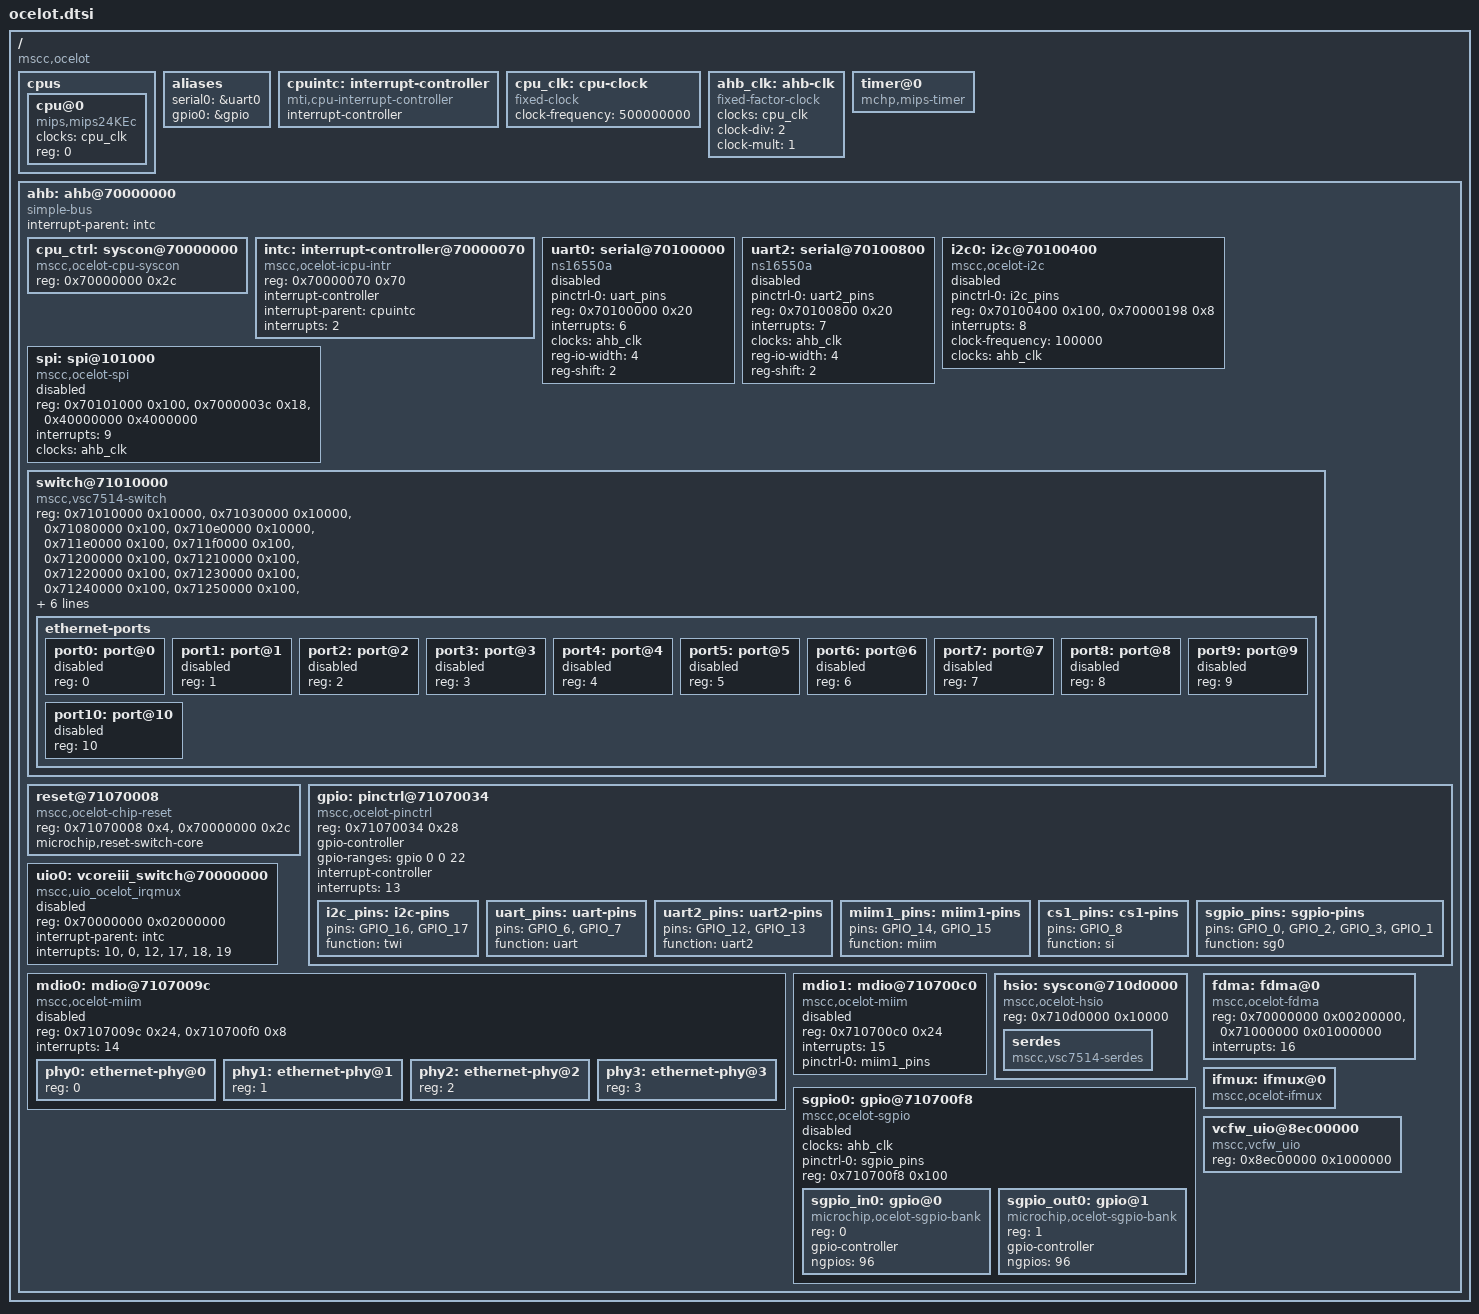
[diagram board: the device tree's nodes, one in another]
// SPDX-License-Identifier: (GPL-2.0 OR MIT)
/* Copyright (c) 2017 Microsemi Corporation */

#include <dt-bindings/gpio/gpio.h>

/ {
	#address-cells = <1>;
	#size-cells = <1>;
	compatible = "mscc,ocelot";

	cpus {
		#address-cells = <1>;
		#size-cells = <0>;

		cpu@0 {
			compatible = "mips,mips24KEc";
			device_type = "cpu";
			clocks = <&cpu_clk>;
			reg = <0>;
		};
	};

	aliases {
		serial0 = &uart0;
		gpio0 = &gpio;
	};

	cpuintc: interrupt-controller {
		#address-cells = <0>;
		#interrupt-cells = <1>;
		interrupt-controller;
		compatible = "mti,cpu-interrupt-controller";
	};

	cpu_clk: cpu-clock {
		compatible = "fixed-clock";
		#clock-cells = <0>;
		clock-frequency = <500000000>;
	};

	ahb_clk: ahb-clk {
		compatible = "fixed-factor-clock";
		#clock-cells = <0>;
		clocks = <&cpu_clk>;
		clock-div = <2>;
		clock-mult = <1>;
	};

	/* Satisfy the platforms need of at least one timer */
	timer@0 {
		compatible = "mchp,mips-timer";
	};

	ahb: ahb@70000000 {
		compatible = "simple-bus";
		#address-cells = <1>;
		#size-cells = <1>;
		ranges;

		interrupt-parent = <&intc>;

		cpu_ctrl: syscon@70000000 {
			compatible = "mscc,ocelot-cpu-syscon", "syscon";
			reg = <0x70000000 0x2c>;
		};

		intc: interrupt-controller@70000070 {
			compatible = "mscc,ocelot-icpu-intr";
			reg = <0x70000070 0x70>;
			#interrupt-cells = <1>;
			interrupt-controller;
			interrupt-parent = <&cpuintc>;
			interrupts = <2>;
		};

		uart0: serial@70100000 {
			pinctrl-0 = <&uart_pins>;
			pinctrl-names = "default";
			compatible = "ns16550a";
			reg = <0x70100000 0x20>;
			interrupts = <6>;
			clocks = <&ahb_clk>;
			reg-io-width = <4>;
			reg-shift = <2>;

			status = "disabled";
		};

		uart2: serial@70100800 {
			pinctrl-0 = <&uart2_pins>;
			pinctrl-names = "default";
			compatible = "ns16550a";
			reg = <0x70100800 0x20>;
			interrupts = <7>;
			clocks = <&ahb_clk>;
			reg-io-width = <4>;
			reg-shift = <2>;

			status = "disabled";
		};

		i2c0: i2c@70100400 {
			compatible = "mscc,ocelot-i2c", "snps,designware-i2c";
			status = "disabled";
			pinctrl-0 = <&i2c_pins>;
			pinctrl-names = "default";
			reg = <0x70100400 0x100>, <0x70000198 0x8>;
			#address-cells = <1>;
			#size-cells = <0>;
			interrupts = <8>;
			clock-frequency = <100000>;
			clocks = <&ahb_clk>;
		};

		spi: spi@101000 {
			compatible = "mscc,ocelot-spi";
			#address-cells = <1>;
			#size-cells = <0>;
			reg = <0x70101000 0x100>, <0x7000003c 0x18>, <0x40000000 0x4000000>;
			interrupts = <9>;
			clocks = <&ahb_clk>;

			status = "disabled";
		};

		switch@71010000 {
			compatible = "mscc,vsc7514-switch";
			reg = <0x71010000 0x10000>,
			      <0x71030000 0x10000>,
			      <0x71080000 0x100>,
			      <0x710e0000 0x10000>,
			      <0x711e0000 0x100>,
			      <0x711f0000 0x100>,
			      <0x71200000 0x100>,
			      <0x71210000 0x100>,
			      <0x71220000 0x100>,
			      <0x71230000 0x100>,
			      <0x71240000 0x100>,
			      <0x71250000 0x100>,
			      <0x71260000 0x100>,
			      <0x71270000 0x100>,
			      <0x71280000 0x100>,
			      <0x71800000 0x80000>,
			      <0x71880000 0x10000>,
			      <0x71040000 0x10000>,
			      <0x71050000 0x10000>,
			      <0x71060000 0x10000>,
			      <0x1a0 0x1c4>;
			reg-names = "sys", "rew", "qs", "ptp", "port0", "port1",
				    "port2", "port3", "port4", "port5", "port6",
				    "port7", "port8", "port9", "port10", "qsys",
				    "ana", "s0", "s1", "s2", "fdma";
			interrupts = <18 21 22 16>;
			interrupt-names = "ptp_rdy", "xtr", "inj", "fdma";

			ethernet-ports {
				#address-cells = <1>;
				#size-cells = <0>;

				port0: port@0 {
					reg = <0>;
					status = "disabled";
				};
				port1: port@1 {
					reg = <1>;
					status = "disabled";
				};
				port2: port@2 {
					reg = <2>;
					status = "disabled";
				};
				port3: port@3 {
					reg = <3>;
					status = "disabled";
				};
				port4: port@4 {
					reg = <4>;
					status = "disabled";
				};
				port5: port@5 {
					reg = <5>;
					status = "disabled";
				};
				port6: port@6 {
					reg = <6>;
					status = "disabled";
				};
				port7: port@7 {
					reg = <7>;
					status = "disabled";
				};
				port8: port@8 {
					reg = <8>;
					status = "disabled";
				};
				port9: port@9 {
					reg = <9>;
					status = "disabled";
				};
				port10: port@10 {
					reg = <10>;
					status = "disabled";
				};
			};
		};

		reset@71070008 {
			compatible = "mscc,ocelot-chip-reset";
			reg = <0x71070008 0x4>, <0x70000000 0x2c>;
			microchip,reset-switch-core;
		};

		gpio: pinctrl@71070034 {
			compatible = "mscc,ocelot-pinctrl";
			reg = <0x71070034 0x28>;
			gpio-controller;
			#gpio-cells = <2>;
			gpio-ranges = <&gpio 0 0 22>;
			interrupt-controller;
			interrupts = <13>;
			#interrupt-cells = <2>;

			i2c_pins: i2c-pins {
				pins = "GPIO_16", "GPIO_17";
				function = "twi";
			};

			uart_pins: uart-pins {
				pins = "GPIO_6", "GPIO_7";
				function = "uart";
			};

			uart2_pins: uart2-pins {
				pins = "GPIO_12", "GPIO_13";
				function = "uart2";
			};

			miim1_pins: miim1-pins {
				pins = "GPIO_14", "GPIO_15";
				function = "miim";
			};

			cs1_pins: cs1-pins {
				pins = "GPIO_8";
				function = "si";
			};

			sgpio_pins: sgpio-pins {
				pins = "GPIO_0", "GPIO_2", "GPIO_3", "GPIO_1";
				function = "sg0";
			};
		};

		uio0: vcoreiii_switch@70000000 {
			compatible = "mscc,uio_ocelot_irqmux";
			reg = <0x70000000 0x02000000>;
			reg-names = "origin1_2";
			interrupt-parent = <&intc>;
			interrupts = <10>, // VCore SW0
				     <0>, <12>,
				     <17>, <18>, <19>;
			interrupt-names = "master",
					  "dev_all", "sgpio0",
					  "oam_vop", "ptp_rdy", "ptp_sync";
			status = "disabled";
		};

		mdio0: mdio@7107009c {
			#address-cells = <1>;
			#size-cells = <0>;
			compatible = "mscc,ocelot-miim";
			reg = <0x7107009c 0x24>, <0x710700f0 0x8>;
			interrupts = <14>;
			status = "disabled";

			phy0: ethernet-phy@0 {
				reg = <0>;
			};
			phy1: ethernet-phy@1 {
				reg = <1>;
			};
			phy2: ethernet-phy@2 {
				reg = <2>;
			};
			phy3: ethernet-phy@3 {
				reg = <3>;
			};
		};

		mdio1: mdio@710700c0 {
			#address-cells = <1>;
			#size-cells = <0>;
			compatible = "mscc,ocelot-miim";
			reg = <0x710700c0 0x24>;
			interrupts = <15>;
			pinctrl-names = "default";
			pinctrl-0 = <&miim1_pins>;
			status = "disabled";
		};

		hsio: syscon@710d0000 {
			compatible = "mscc,ocelot-hsio", "syscon", "simple-mfd";
			reg = <0x710d0000 0x10000>;

			serdes: serdes {
				compatible = "mscc,vsc7514-serdes";
				#phy-cells = <2>;
			};
		};

		sgpio0: gpio@710700f8 {
			#address-cells = <1>;
			#size-cells = <0>;
			compatible = "mscc,ocelot-sgpio";
			status = "disabled";
			clocks = <&ahb_clk>;
			pinctrl-0 = <&sgpio_pins>;
			pinctrl-names = "default";
			reg = <0x710700f8 0x100>;
			sgpio_in0: gpio@0 {
				compatible = "microchip,ocelot-sgpio-bank";
				reg = <0>;
				gpio-controller;
				#gpio-cells = <3>;
				ngpios = <96>;
			};
			sgpio_out0: gpio@1 {
				compatible = "microchip,ocelot-sgpio-bank";
				reg = <1>;
				gpio-controller;
				#gpio-cells = <3>;
				ngpios = <96>;
			};
		};

		fdma: fdma@0 {
			compatible = "mscc,ocelot-fdma";
			status = "okay";
			reg = <0x70000000 0x00200000>, <0x71000000 0x01000000>;
			interrupts = <16>;
		};

		ifmux: ifmux@0 {
			compatible = "mscc,ocelot-ifmux";
			status = "okay";
		};

		vcfw_uio@8ec00000 {
			/* Firmware ramload memory */
			compatible = "mscc,vcfw_uio";
			reg = <0x8ec00000 0x1000000>;
		};
	};
};
